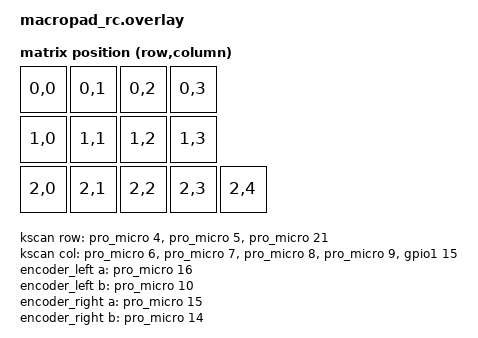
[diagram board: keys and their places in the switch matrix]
// This file was generated from a template. Edit it to match your keyboard.
// See https://zmk.dev/docs/development/hardware-integration/new-shield for more
// instructions.

#include <dt-bindings/zmk/matrix_transform.h>
#include <dt-bindings/led/led.h>

#include "macropad_rc-layouts.dtsi"

/ {
    chosen {
        zmk,kscan = &kscan;
        zmk,physical-layout = &default_layout;
        zmk,underglow = &led_strip;
		zephyr,display = &oled;
    };

    sensors: sensors {
        compatible = "zmk,keymap-sensors";
        sensors = <&encoder_left &encoder_right>;
        triggers-per-rotation = <20>;
    };

    kscan: kscan {
        // If the hardware does not use a switch matrix, change this to the
        // appropriate driver and update the properties below to match.
        // See https://zmk.dev/docs/config/kscan for supported key scan drivers.
        compatible = "zmk,kscan-gpio-matrix";
        // Set this to "col2row" or "row2col" to match the hardware. If using
        // "row2col", change the col-gpios to (GPIO_ACTIVE_HIGH | GPIO_PULL_DOWN)
        // and the row-gpios to GPIO_ACTIVE_HIGH.
        diode-direction = "row2col";
        wakeup-source;

        // Replace these comments with the GPIO pins in the matrix.
        // See https://zmk.dev/docs/development/hardware-integration/new-shield#shield-overlays
        row-gpios
            = <&pro_micro 4 GPIO_ACTIVE_HIGH>  // Row 1 (D4, P0.22)
            , <&pro_micro 5 GPIO_ACTIVE_HIGH>  // Row 2 (D5, P0.24)
            , <&pro_micro 21 GPIO_ACTIVE_HIGH> // Row 3 (A3 / D21, P0.31)
            ;

        col-gpios
            = <&pro_micro 6 (GPIO_ACTIVE_HIGH | GPIO_PULL_DOWN)>  // Col 1 (D6, P1.00)
            , <&pro_micro 7 (GPIO_ACTIVE_HIGH | GPIO_PULL_DOWN)>  // Col 2 (D8, P0.11)
            , <&pro_micro 8 (GPIO_ACTIVE_HIGH | GPIO_PULL_DOWN)>  // Col 3 (D7, P1.04)
            , <&pro_micro 9 (GPIO_ACTIVE_HIGH | GPIO_PULL_DOWN)>  // Col 4 (D6, P1.06)

            , <&gpio1 15 (GPIO_ACTIVE_LOW | GPIO_PULL_UP)> // Extra Key Column (A0 / D18, P1.15)
            ;
    };

    default_transform: default_transform {
        // See https://zmk.dev/docs/development/hardware-integration/new-shield#matrix-transform
        // for how to configure this
        compatible = "zmk,matrix-transform";
        columns = <5>;
        rows = <3>;

        map = <
            RC(0,0) RC(0,1) RC(0,2) RC(0,3)
            RC(1,0) RC(1,1) RC(1,2) RC(1,3)
            RC(2,0) RC(2,1) RC(2,2) RC(2,3) RC(2,4) // Extra key sits at Row 3, Col -1 electrically
        >;
    };

    encoder_left: encoder_left {
        compatible = "alps,ec11";
        a-gpios = <&pro_micro 16 (GPIO_ACTIVE_HIGH | GPIO_PULL_UP)>; // RE1A (D16 -> P0.10)
        b-gpios = <&pro_micro 10 (GPIO_ACTIVE_HIGH | GPIO_PULL_UP)>; // RE1B (D10 -> P0.09)
        steps = <80>;
        status = "okay"; // active
    };

    encoder_right: encoder_right {
        compatible = "alps,ec11";
        a-gpios = <&pro_micro 15 (GPIO_ACTIVE_HIGH | GPIO_PULL_UP)>; // RE2A (D15 -> P1.13)
        b-gpios = <&pro_micro 14 (GPIO_ACTIVE_HIGH | GPIO_PULL_UP)>; // RE2B (D14 -> P1.11)
        steps = <80>;
        status = "disabled"; // inactive - not wired in
    };
};

&pinctrl {
    spi1_default: spi1_default {
        group1 {
            psels = <NRF_PSEL(SPIM_MOSI, 0, 29)>; // (A2 / D20 -> P0.29)
        };
    };

    spi1_sleep: spi1_sleep {
        group1 {
            psels = <NRF_PSEL(SPIM_MOSI, 0, 29)>;
            low-power-enable;
        };
    };
};

&usbd {
	status = "okay";
};

&spi1 {
    compatible = "nordic,nrf-spim";
    label = "led_strip";
    status = "okay";
    
    pinctrl-0 = <&spi1_default>;
    pinctrl-1 = <&spi1_sleep>;
    pinctrl-names = "default", "sleep";

    led_strip: ws2812@0 {
        compatible = "worldsemi,ws2812-spi";

        reg = <0>;
        spi-max-frequency = <4000000>;

        chain-length = <13>; // Total individual key LEDs
        spi-one-frame = <0x70>;
        spi-zero-frame = <0x40>;
        color-mapping = <LED_COLOR_ID_GREEN LED_COLOR_ID_RED LED_COLOR_ID_BLUE>; 
    };
};

/* Force the VCC pin on instantly during pre-kernel boot */
&gpio0 {
    vcc_hog {
        gpio-hog;
        gpios = <13 GPIO_ACTIVE_HIGH>;
        output-high;
    };
};


&pro_micro_i2c {
    status = "okay";

    oled: ssd1306@3c {
        compatible = "solomon,ssd1306fb";
        reg = <0x3c>;
        label = "DISPLAY";
        width = <128>;
        height = <32>;
        segment-offset = <0>;
        page-offset = <0>;
        display-offset = <0>;
        multiplex-ratio = <31>;
        segment-remap;
        com-invdir;
        com-sequential;
        prechargep = <0x22>;
    };
};
